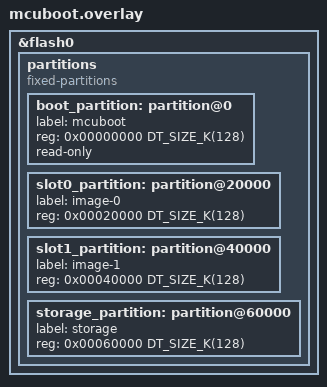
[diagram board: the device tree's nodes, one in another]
/*
 * Flash partition layout shared with MCUboot (all aligned to 128KB sectors).
 *
 * Remove ranges from flash0 to prevent DT_FIXED_PARTITION_ADDR from
 * double-adding the flash base address.
 */
&flash0 {
    /delete-property/ ranges;

    partitions {
        compatible = "fixed-partitions";
        #address-cells = <1>;
        #size-cells = <1>;
        ranges;

        boot_partition: partition@0 {
            label = "mcuboot";
            reg = <0x00000000 DT_SIZE_K(128)>;
            read-only;
        };

        slot0_partition: partition@20000 {
            label = "image-0";
            reg = <0x00020000 DT_SIZE_K(128)>;
        };

        slot1_partition: partition@40000 {
            label = "image-1";
            reg = <0x00040000 DT_SIZE_K(128)>;
        };

        storage_partition: partition@60000 {
            label = "storage";
            reg = <0x00060000 DT_SIZE_K(128)>;
        };
    };
};
